AUTOSAR XML (schema 00050)
package /ComponentTypes
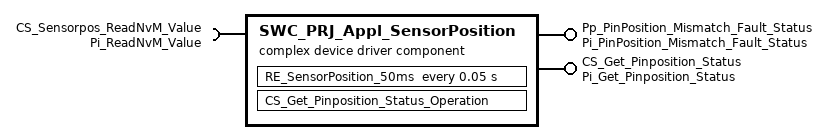
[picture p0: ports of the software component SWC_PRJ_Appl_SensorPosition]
  complex device driver sw component type SWC_PRJ_Appl_SensorPosition
    provide port Pp_PinPosition_Mismatch_Fault_Status: nonqueued-sender-com-spec=data-element=De_PinPosition_Mismatch_Fault_Status, provided-interface=Pi_PinPosition_Mismatch_Fault_Status
    require port CS_Sensorpos_ReadNvM_Value: client-com-spec=Operation, required-interface=Pi_ReadNvM_Value
    provide port CS_Get_Pinposition_Status: server-com-spec{operation=Operation, queue-length=1}, provided-interface=Pi_Get_Pinposition_Status
    behavior SWC_PRJ_Appl_SensorPosition_InternalBehavior: handle-termination-and-restart=NO-SUPPORT
      timing event TMT_RE_SensorPosition_50ms: start-on-event=RE_SensorPosition_50ms, period=0.05
      operation invoked event OIT_CS_Get_Pinposition_Status_Operation_CS_Get_Pinposition_Status_Operation: start-on-event=CS_Get_Pinposition_Status_Operation, operation=CS_Get_Pinposition_Status.Operation
      runnable RE_SensorPosition_50ms
        data-send-points:
          access SEND_Pp_PinPosition_Mismatch_Fault_Status_De_PinPosition_Mismatch_Fault_Status: accessed-variable=Pp_PinPosition_Mismatch_Fault_Status.De_PinPosition_Mismatch_Fault_Status
        sync call SC_CS_Sensorpos_ReadNvM_Value_Operation: operation=CS_Sensorpos_ReadNvM_Value.Operation
      runnable CS_Get_Pinposition_Status_Operation
  swc implementation SWC_PRJ_Appl_SensorPosition_Implementation: behavior=SWC_PRJ_Appl_SensorPosition_InternalBehavior
